# ATSAME51J18A register map
Vendor: Microchip Technology; Series: SAME51; File version: 0
CPU: CM4 r0p1, selectable endian, MPU, FPU, 3 interrupt priority bits
Registers are 32-bit, read-write, reset 0x0 unless marked. A register's access mark holds for its fields unless they carry their own. Offsets are from the block's base; [hi:lo] are bit positions; lines under a group give offsets from that group; {n}, {i} and the like mark numbered series.

## FREQM — Frequency Meter
Base 0x40002C00; register names take the prefix FREQM_
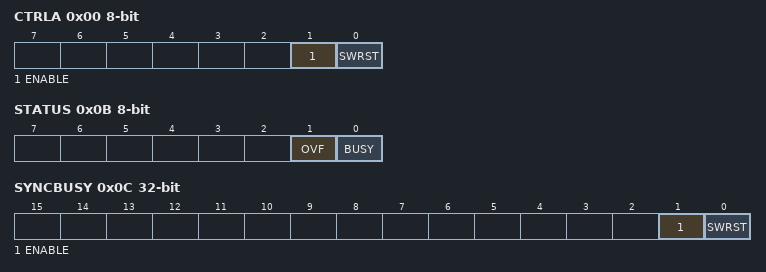
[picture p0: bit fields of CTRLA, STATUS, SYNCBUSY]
0x00 CTRLA 8-bit — Control A Register
  [1] ENABLE
  [0] SWRST — Software Reset
0x01 CTRLB 8-bit wo — Control B Register
  [0] START — Start Measurement
0x02 CFGA 16-bit — Config A register
  [7:0] REFNUM — Number of Reference Clock Cycles
0x08 INTENCLR 8-bit — Interrupt Enable Clear Register
  [0] DONE — Measurement Done Interrupt Enable
0x09 INTENSET 8-bit — Interrupt Enable Set Register
  [0] DONE — Measurement Done Interrupt Enable
0x0A INTFLAG 8-bit — Interrupt Flag Register
  [0] DONE write-1-clears — Measurement Done
0x0B STATUS 8-bit
  [1] OVF write-1-clears — Sticky Count Value Overflow
  [0] BUSY ro — FREQM Status
0x0C SYNCBUSY ro — Synchronization Busy Register
  [1] ENABLE
  [0] SWRST — Software Reset
0x10 VALUE ro — Count Value Register
  [23:0] VALUE — Measurement Value

## GCLK — Generic Clock Generator
Base 0x40001C00; register names take the prefix GCLK_
0x00 CTRLA 8-bit — Control
  [0] SWRST — Software Reset
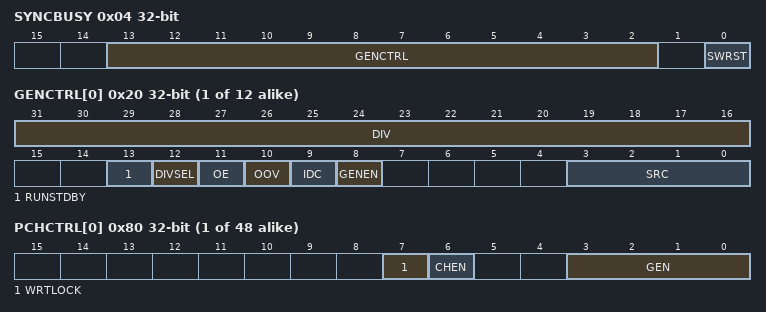
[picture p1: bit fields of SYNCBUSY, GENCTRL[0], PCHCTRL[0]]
0x04 SYNCBUSY ro — Synchronization Busy
  [13:2] GENCTRL — Generic Clock Generator Control n Synchronization Busy bits
    1=GCLK0 (Generic clock generator 0); 2=GCLK1 (Generic clock generator 1); 4=GCLK2 (Generic clock generator 2); 8=GCLK3 (Generic clock generator 3); 16=GCLK4 (Generic clock generator 4); 32=GCLK5 (Generic clock generator 5); 64=GCLK6 (Generic clock generator 6); 128=GCLK7 (Generic clock generator 7); 0x100=GCLK8 (Generic clock generator 8); 0x200=GCLK9 (Generic clock generator 9); 0x400=GCLK10 (Generic clock generator 10); 0x800=GCLK11 (Generic clock generator 11)
  [0] SWRST — Software Reset Synchroniation Busy bit
{0x20+4i} GENCTRL[{i}] (i=0..11) — Generic Clock Generator Control
  [31:16] DIV — Division Factor
  [13] RUNSTDBY — Run in Standby
  [12] DIVSEL — Divide Selection
    0=DIV1 (Divide input directly by divider factor); 1=DIV2 (Divide input by 2^(divider factor+ 1))
  [11] OE — Output Enable
  [10] OOV — Output Off Value
  [9] IDC — Improve Duty Cycle
  [8] GENEN — Generic Clock Generator Enable
  [3:0] SRC — Source Select
    0=XOSC0 (XOSC0 oscillator output); 1=XOSC1 (XOSC1 oscillator output); 2=GCLKIN (Generator input pad); 3=GCLKGEN1 (Generic clock generator 1 output); 4=OSCULP32K (OSCULP32K oscillator output); 5=XOSC32K (XOSC32K oscillator output); 6=DFLL (DFLL output); 7=DPLL0 (DPLL0 output); 8=DPLL1 (DPLL1 output)
{0x80+4i} PCHCTRL[{i}] (i=0..47) — Peripheral Clock Control
  [7] WRTLOCK — Write Lock
  [6] CHEN — Channel Enable
  [3:0] GEN — Generic Clock Generator
    {v}=GCLK{v} (Generic clock generator {v}) (v=0..11)

## HMATRIX — HSB Matrix
Base 0x4100C000; register names take the prefix HMATRIXB_
{0x80+8i} PRS[{i}] (i=0..15) group
  0x00 PRAS — Priority A for Slave
  0x04 PRBS — Priority B for Slave

## ICM — Integrity Check Monitor
Base 0x42002C00; register names take the prefix ICM_
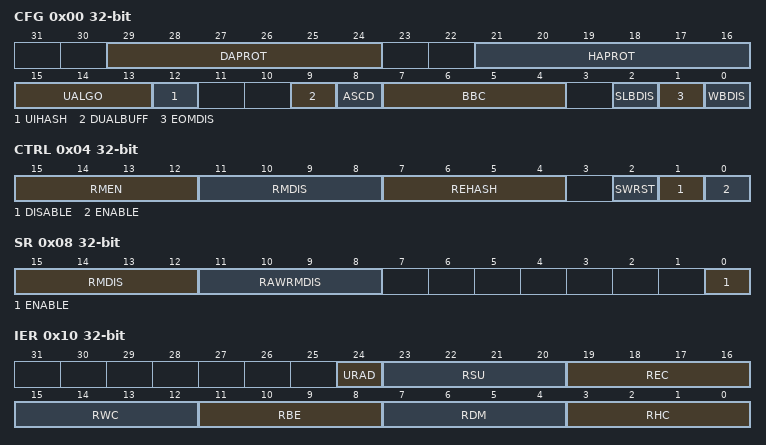
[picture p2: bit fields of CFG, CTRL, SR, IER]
0x00 CFG — Configuration
  [29:24] DAPROT — Region Descriptor Area Protection
  [21:16] HAPROT — Region Hash Area Protection
  [15:13] UALGO — User SHA Algorithm
    0=SHA1 (SHA1 Algorithm); 1=SHA256 (SHA256 Algorithm); 4=SHA224 (SHA224 Algorithm)
  [12] UIHASH — User Initial Hash Value
  [9] DUALBUFF — Dual Input Buffer
  [8] ASCD — Automatic Switch To Compare Digest
  [7:4] BBC — Bus Burden Control
  [2] SLBDIS — Secondary List Branching Disable
  [1] EOMDIS — End of Monitoring Disable
  [0] WBDIS — Write Back Disable
0x04 CTRL wo — Control
  [15:12] RMEN — Region Monitoring Enable
  [11:8] RMDIS — Region Monitoring Disable
  [7:4] REHASH — Recompute Internal Hash
  [2] SWRST — Software Reset
  [1] DISABLE — ICM Disable Register
  [0] ENABLE — ICM Enable
0x08 SR ro — Status
  [15:12] RMDIS — Region Monitoring Disabled Status
  [11:8] RAWRMDIS — RAW Region Monitoring Disabled Status
  [0] ENABLE — ICM Controller Enable Register
0x10 IER wo — Interrupt Enable
  [24] URAD — Undefined Register Access Detection Interrupt Enable
  [23:20] RSU — Region Status Updated Interrupt Disable
  [19:16] REC — Region End bit Condition Detected Interrupt Enable
  [15:12] RWC — Region Wrap Condition detected Interrupt Enable
  [11:8] RBE — Region Bus Error Interrupt Enable
  [7:4] RDM — Region Digest Mismatch Interrupt Enable
  [3:0] RHC — Region Hash Completed Interrupt Enable
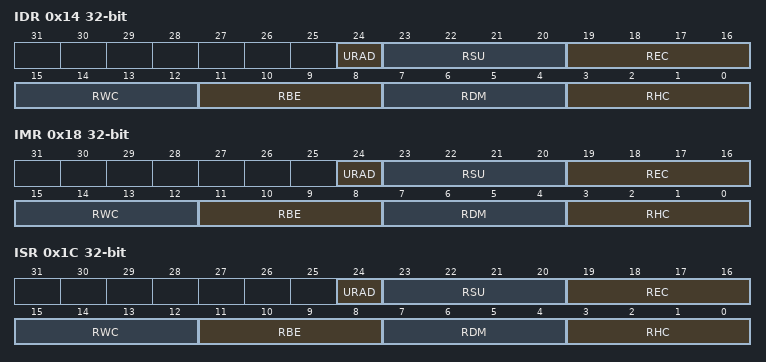
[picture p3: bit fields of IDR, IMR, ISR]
0x14 IDR wo — Interrupt Disable
  [24] URAD — Undefined Register Access Detection Interrupt Disable
  [23:20] RSU — Region Status Updated Interrupt Disable
  [19:16] REC — Region End bit Condition detected Interrupt Disable
  [15:12] RWC — Region Wrap Condition Detected Interrupt Disable
  [11:8] RBE — Region Bus Error Interrupt Disable
  [7:4] RDM — Region Digest Mismatch Interrupt Disable
  [3:0] RHC — Region Hash Completed Interrupt Disable
0x18 IMR ro — Interrupt Mask
  [24] URAD — Undefined Register Access Detection Interrupt Mask
  [23:20] RSU — Region Status Updated Interrupt Mask
  [19:16] REC — Region End bit Condition Detected Interrupt Mask
  [15:12] RWC — Region Wrap Condition Detected Interrupt Mask
  [11:8] RBE — Region Bus Error Interrupt Mask
  [7:4] RDM — Region Digest Mismatch Interrupt Mask
  [3:0] RHC — Region Hash Completed Interrupt Mask
0x1C ISR ro — Interrupt Status
  [24] URAD — Undefined Register Access Detection Status
  [23:20] RSU — Region Status Updated Detected
  [19:16] REC — Region End bit Condition Detected
  [15:12] RWC — Region Wrap Condition Detected
  [11:8] RBE — Region Bus Error
  [7:4] RDM — Region Digest Mismatch
  [3:0] RHC — Region Hash Completed
0x20 UASR ro — Undefined Access Status
  [2:0] URAT — Undefined Register Access Trace
    0=UNSPEC_STRUCT_MEMBER (Unspecified structure member set to one detected when the descriptor is loaded); 1=CFG_MODIFIED (CFG modified during active monitoring); 2=DSCR_MODIFIED (DSCR modified during active monitoring); 3=HASH_MODIFIED (HASH modified during active monitoring); 4=READ_ACCESS (Write-only register read access)
0x30 DSCR — Region Descriptor Area Start Address
  [31:6] DASA — Descriptor Area Start Address
0x34 HASH — Region Hash Area Start Address
  [31:7] HASA — Hash Area Start Address
{0x38+4i} UIHVAL[{i}] (i=0..7) wo — User Initial Hash Value n
  [31:0] VAL — Initial Hash Value
